# PY32F0xx_DFP register map
Vendor: Puya; Series: PY32F0; File version: 1.0.0
CPU: CM0+ r0p1, little endian, no MPU, no FPU, 4 interrupt priority bits
Registers are 32-bit, read-write, reset 0x0 unless marked. A register's access mark holds for its fields unless they carry their own. Offsets are from the block's base; [hi:lo] are bit positions; {n}, {i} and the like mark numbered series.

## GPIOA — General-purpose I/Os
Base 0x50000000
Same registers: GPIOB 0x50000400, GPIOC 0x50000800, GPIOF 0x50001400
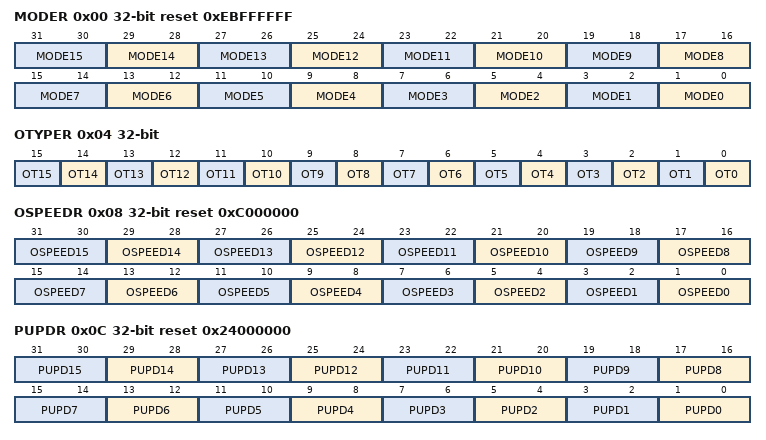
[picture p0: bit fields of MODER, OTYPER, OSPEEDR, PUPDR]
0x00 MODER reset 0xEBFFFFFF — GPIO port mode register
  [2n+1:2n] MODE{n} (n=0..15) — Port x configuration bits (y=0-15)
0x04 OTYPER — GPIO port output type register
  [n] OT{n} (n=0..15) — Port x configuration bits (y=0-15)
0x08 OSPEEDR reset 0xC000000 — GPIO port output speed register
  [2n+1:2n] OSPEED{n} (n=0..15) — Port x configuration bits (y=0-15)
0x0C PUPDR reset 0x24000000 — GPIO port pull-up/pull-down register
  [2n+1:2n] PUPD{n} (n=0..15) — Port x configuration bits (y=0-15)
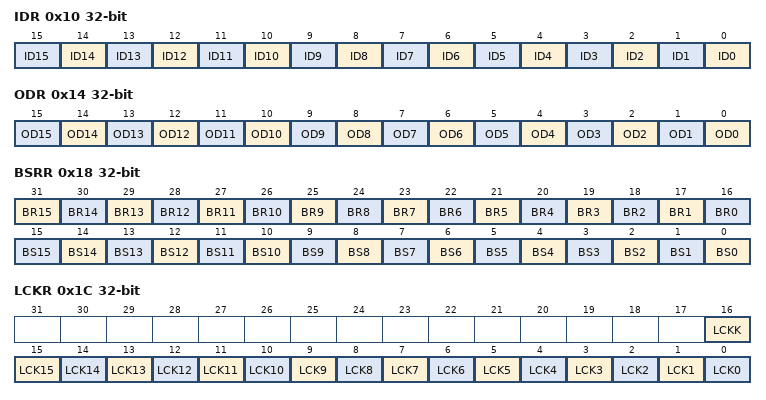
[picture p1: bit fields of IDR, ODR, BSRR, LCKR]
0x10 IDR ro — GPIO port input data register
  [n] ID{n} (n=0..15) — Port input data (y=0-15)
0x14 ODR — GPIO port output data register
  [n] OD{n} (n=0..15) — Port output data (y=0-15)
0x18 BSRR wo — GPIO port bit set/reset register
  [n+16] BR{n} (n=1..15) — Port x reset bit y (y=0-15)
  [16] BR0 — Port x set bit y (y=0-15)
  [n] BS{n} (n=0..15) — Port x set bit y (y=0-15)
0x1C LCKR — GPIO port configuration lock register
  [16] LCKK — Port x lock (LCKK)
  [n] LCK{n} (n=0..15) — Port x lock bit y (y=0-15)
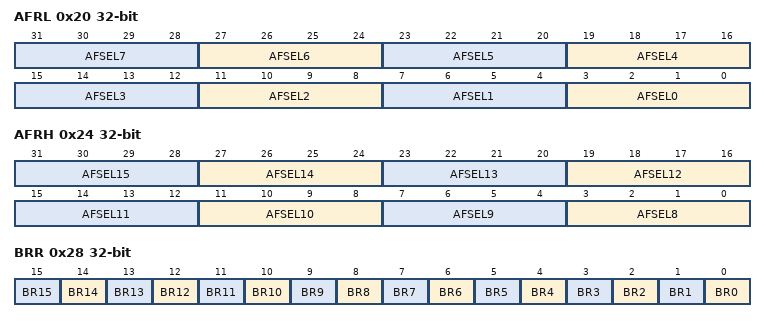
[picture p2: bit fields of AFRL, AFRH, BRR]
0x20 AFRL — GPIO alternate function low register
  [4n+3:4n] AFSEL{n} (n=0..7) — Alternate function selection for port x bit y (y=0-7)
0x24 AFRH — GPIO alternate function high register
  [4n-29:4n-32] AFSEL{n} (n=8..15) — Alternate function selection for port x bit y (y=8-15)
0x28 BRR wo — port bit reset register
  [n] BR{n} (n=0..15) — Port Reset bit

## HDIV — Hardware Divider
Base 0x40023800
0x00 DEND — Dividend
0x04 SOR — Divisor
0x08 QUOT ro — Quotient
0x0C REMA ro — Remainder
0x10 SIGN — des SIGN
  [0] DIV_SIGN — des DIV_SIGN
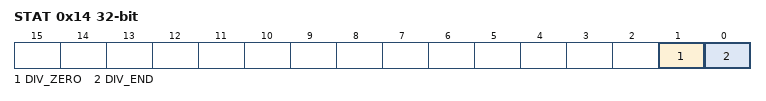
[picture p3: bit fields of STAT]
0x14 STAT — des SIGN
  [1] DIV_ZERO — des DIV_ZERO
  [0] DIV_END — des DIV_END

## I2C1 — Inter integrated circuit
Base 0x40005400
Same registers: I2C2 0x40005800
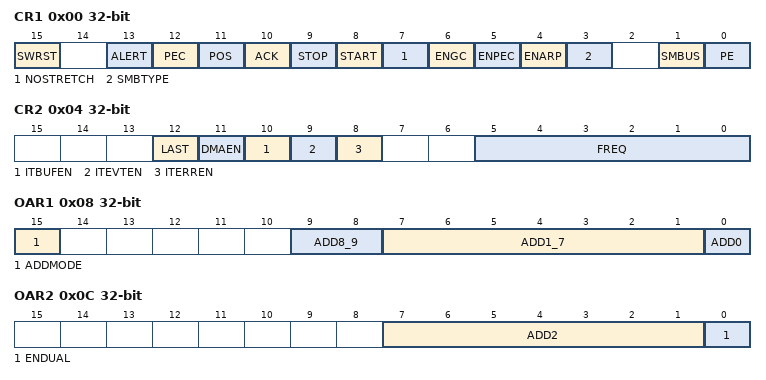
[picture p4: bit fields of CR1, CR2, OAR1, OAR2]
0x00 CR1
  [15] SWRST, [13] ALERT, [12] PEC, [11] POS, [10] ACK, [9] STOP, [8] START, [7] NOSTRETCH, [6] ENGC, [5] ENPEC, [4] ENARP, [3] SMBTYPE, [1] SMBUS, [0] PE
0x04 CR2
  [12] LAST, [11] DMAEN, [10] ITBUFEN, [9] ITEVTEN, [8] ITERREN, [5:0] FREQ
0x08 OAR1
  [15] ADDMODE, [9:8] ADD8_9, [7:1] ADD1_7, [0] ADD0
0x0C OAR2
  [7:1] ADD2, [0] ENDUAL
0x10 DR
  [7:0] DR
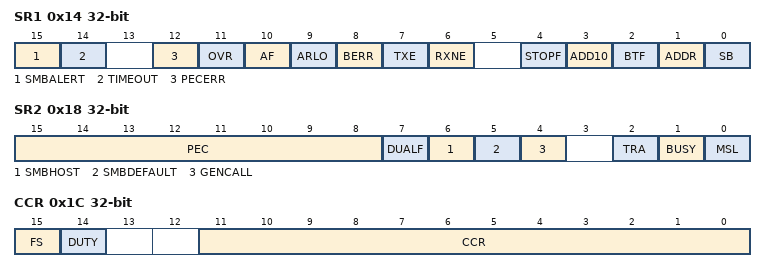
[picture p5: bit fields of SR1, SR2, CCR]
0x14 SR1
  [15] SMBALERT, [14] TIMEOUT, [12] PECERR, [11] OVR, [10] AF, [9] ARLO, [8] BERR, [7] TXE ro, [6] RXNE ro, [4] STOPF ro, [3] ADD10 ro, [2] BTF ro, [1] ADDR ro, [0] SB ro
0x18 SR2 ro
  [15:8] PEC, [7] DUALF, [6] SMBHOST, [5] SMBDEFAULT, [4] GENCALL, [2] TRA, [1] BUSY, [0] MSL
0x1C CCR
  [15] FS, [14] DUTY, [11:0] CCR
0x20 TRISE reset 0x2
  [5:0] TRISE

## IWDG — Independent watchdog
Base 0x40003000
0x00 KR wo — Key register (IWDG_KR)
  [15:0] KEY — Key value
0x04 PR — Prescaler register (IWDG_PR)
  [2:0] PR — Prescaler divider
0x08 RLR reset 0xFFF — Reload register (IWDG_RLR)
  [11:0] RL — Watchdog counter reload value
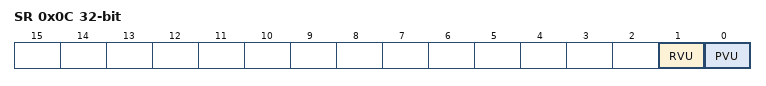
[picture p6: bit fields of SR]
0x0C SR ro — Status register (IWDG_SR)
  [1] RVU — Watchdog counter reload value update
  [0] PVU — Watchdog prescaler value update

## LCD — LCD CONTROLLER
Base 0x40002400
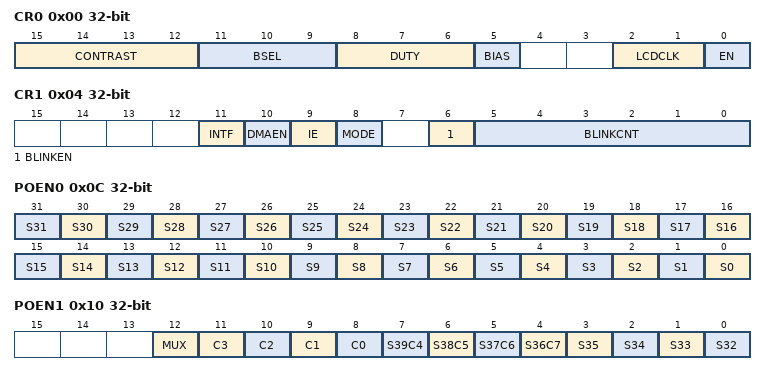
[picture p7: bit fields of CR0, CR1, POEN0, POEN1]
0x00 CR0 — Control register
  [15:12] CONTRAST, [11:9] BSEL, [8:6] DUTY, [5] BIAS, [2:1] LCDCLK, [0] EN
0x04 CR1
  [11] INTF, [10] DMAEN, [9] IE, [8] MODE, [6] BLINKEN, [5:0] BLINKCNT
0x08 INTCLR
  [10] INTF_CLR
0x0C POEN0
  [n] S{n} (n=0..31)
0x10 POEN1
  [12] MUX
  [n+8] C{n} (n=0..3)
  [7] S39C4 — S39
  [6] S38C5 — S38
  [5] S37C6 — S37
  [4] S36C7 — S36
  [n-32] S{n} (n=32..35)
{0x14+4i} RAM{i} (i=0..7) — des RAM{i}
  [31:0] D — des D
{0x14+4i} RAM{i} (i=8..15) — des RAM{i}
  [7:0] D — des D

## LPTIM1 — Low power timer
Base 0x40007C00
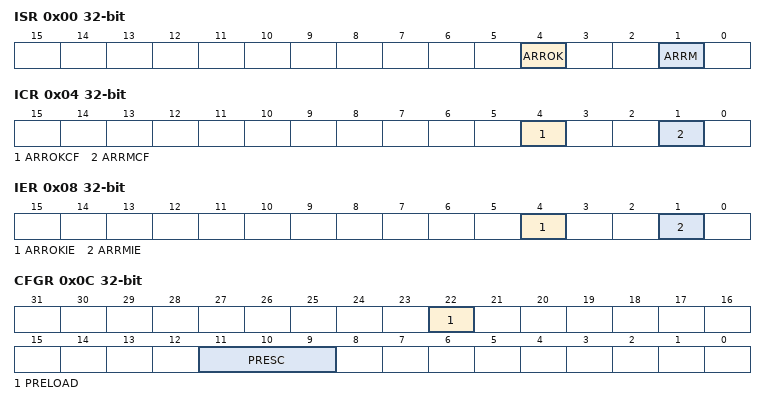
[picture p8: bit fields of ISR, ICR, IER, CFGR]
0x00 ISR ro — Interrupt and Status Register
  [4] ARROK — Autoreload match update OK
  [1] ARRM — Autoreload match
0x04 ICR wo — Interrupt Clear Register
  [4] ARROKCF — Autoreload match update OK Clear Flag
  [1] ARRMCF — Autoreload match Clear Flag
0x08 IER — Interrupt Enable Register
  [4] ARROKIE — Autoreload match update OK Interrupt Enable
  [1] ARRMIE — Autoreload matchInterrupt Enable
0x0C CFGR — Configuration Register
  [22] PRELOAD — Registers update mode
  [11:9] PRESC — Clock prescaler
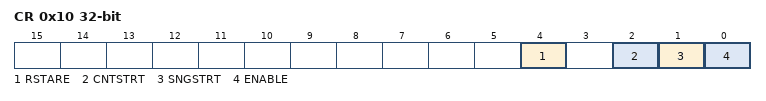
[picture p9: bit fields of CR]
0x10 CR — Control Register
  [4] RSTARE — Reset after read enable
  [2] CNTSTRT
  [1] SNGSTRT — LPTIM start in single mode
  [0] ENABLE — LPTIM Enable
0x18 ARR reset 0x1 — Autoreload Register
  [15:0] ARR — Auto reload value
0x1C CNT ro — Counter Register
  [15:0] CNT — Counter value
